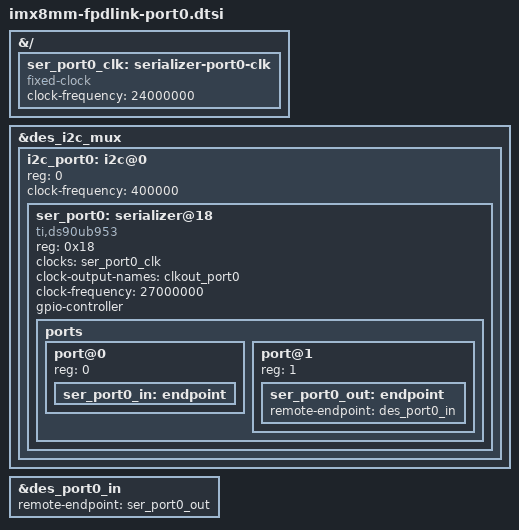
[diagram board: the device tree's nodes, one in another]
// SPDX-License-Identifier: (GPL-2.0+ OR MIT)
/*
 * Copyright (C) 2022 PHYTEC Messtechnik GmbH
 * Author: Stefan Riedmueller <s.riedmueller@phytec.de>
 */

/dts-v1/;
/plugin/;

#include "imx8mm-fpdlink.dtsi"

&{/} {
	ser_port0_clk: serializer-port0-clk {
		#clock-cells = <0>;
		compatible = "fixed-clock";
		clock-frequency = <24000000>;
	};
};

&des_i2c_mux {
	i2c_port0: i2c@0 {
		#address-cells = <1>;
		#size-cells = <0>;
		reg = <0>;
		clock-frequency = <400000>;

		ser_port0: serializer@18 {
			compatible = "ti,ds90ub953";
			reg = <0x18>;

			clocks = <&ser_port0_clk>;
			clock-names = "refclk";

			#clock-cells = <0>;
			clock-output-names = "clkout_port0";
			clock-frequency = <27000000>;

			gpio-controller;
			#gpio-cells = <2>;

			ports {
				#address-cells = <0x1>;
				#size-cells = <0x0>;
				port@0 {
					reg = <0>;
					ser_port0_in: endpoint {};
				};

				port@1 {
					reg = <1>;
					ser_port0_out: endpoint {
						remote-endpoint = <&des_port0_in>;
					};
				};
			};
		};
	};
};

&des_port0_in {
	remote-endpoint = <&ser_port0_out>;
};
